VERSION ""

NS_ :

BS_:

BU_: XXX X

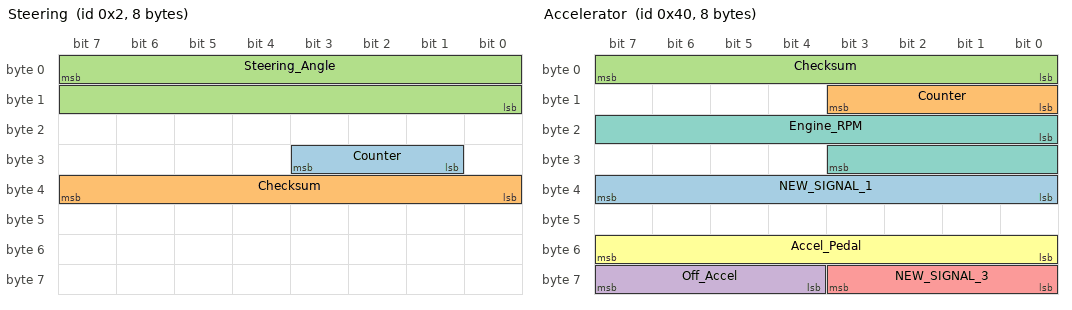
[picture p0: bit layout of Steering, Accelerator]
BO_ 2 Steering: 8 XXX
 SG_ Counter : 25|3@1+ (1,0) [0|7] "" XXX
 SG_ Checksum : 39|8@0+ (1,0) [0|255] "" XXX
 SG_ Steering_Angle : 7|16@0- (0.1,0) [0|65535] "" XXX

BO_ 64 Accelerator: 8 XXX
 SG_ NEW_SIGNAL_1 : 32|8@1+ (1,0) [0|255] "" XXX
 SG_ Counter : 11|4@0+ (1,0) [0|255] "" XXX
 SG_ Checksum : 7|8@0- (1,0) [0|255] "" XXX
 SG_ Off_Accel : 63|4@0+ (1,0) [0|7] "" XXX
 SG_ NEW_SIGNAL_3 : 56|4@1+ (1,0) [0|255] "" XXX
 SG_ Accel_Pedal : 55|8@0+ (1,0) [0|255] "" XXX
 SG_ Engine_RPM : 16|12@1+ (1,0) [0|255] "" XXX

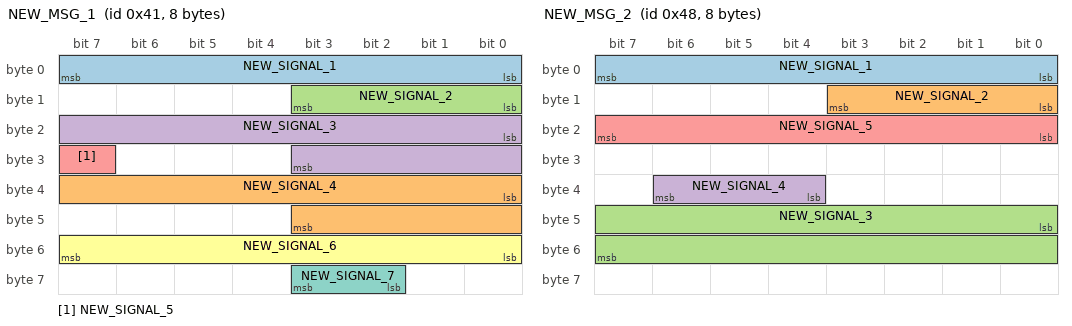
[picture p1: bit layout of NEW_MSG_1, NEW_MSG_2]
BO_ 65 NEW_MSG_1: 8 XXX
 SG_ NEW_SIGNAL_1 : 7|8@0+ (1,0) [0|255] "" XXX
 SG_ NEW_SIGNAL_4 : 32|12@1+ (1,0) [0|255] "" XXX
 SG_ NEW_SIGNAL_2 : 8|4@1+ (1,0) [0|15] "" XXX
 SG_ NEW_SIGNAL_3 : 16|12@1+ (1,0) [0|1] "" XXX
 SG_ NEW_SIGNAL_5 : 31|1@0+ (1,0) [0|15] "" XXX
 SG_ NEW_SIGNAL_6 : 48|8@1+ (1,0) [0|63] "" XXX
 SG_ NEW_SIGNAL_7 : 59|2@0+ (1,0) [0|255] "" XXX

BO_ 72 NEW_MSG_2: 8 XXX
 SG_ NEW_SIGNAL_1 : 7|8@0+ (1,0) [0|255] "" XXX
 SG_ NEW_SIGNAL_2 : 8|4@1+ (1,0) [0|15] "" XXX
 SG_ NEW_SIGNAL_3 : 40|16@1+ (1,0) [0|255] "" XXX
 SG_ NEW_SIGNAL_4 : 38|3@0+ (1,0) [0|255] "" XXX
 SG_ NEW_SIGNAL_5 : 16|8@1+ (1,0) [0|255] "" XXX

BO_ 316 NEW_MSG_3: 8 XXX

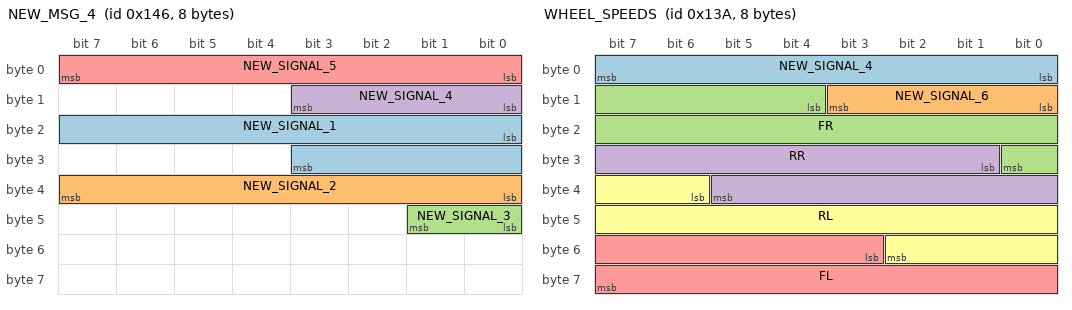
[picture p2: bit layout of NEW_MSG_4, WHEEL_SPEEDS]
BO_ 326 NEW_MSG_4: 8 XXX
 SG_ NEW_SIGNAL_1 : 16|12@1+ (1,0) [0|255] "" XXX
 SG_ NEW_SIGNAL_2 : 32|8@1+ (1,0) [0|255] "" XXX
 SG_ NEW_SIGNAL_3 : 40|2@1+ (1,0) [0|255] "" XXX
 SG_ NEW_SIGNAL_4 : 8|4@1+ (1,0) [0|15] "" XXX
 SG_ NEW_SIGNAL_5 : 7|8@0+ (1,0) [0|255] "" XXX

BO_ 315 G_Sensor: 8 XXX
 SG_ longitudinal : 63|8@0- (1,0) [0|255] "" XXX
 SG_ Latitudinal : 48|8@1- (1,0) [0|255] "" XXX

BO_ 314 WHEEL_SPEEDS: 8 XXX
 SG_ NEW_SIGNAL_4 : 7|8@0+ (1,0) [0|255] "" XXX
 SG_ NEW_SIGNAL_6 : 8|4@1+ (1,0) [0|15] "" XXX
 SG_ FR : 12|13@1+ (0.05747,0) [0|255] "kph" XXX
 SG_ RR : 25|13@1+ (0.05747,0) [0|255] "kph" XXX
 SG_ FL : 51|13@1+ (0.05747,0) [0|255] "kph" XXX
 SG_ RL : 38|13@1+ (0.05747,0) [0|255] "kph" XXX

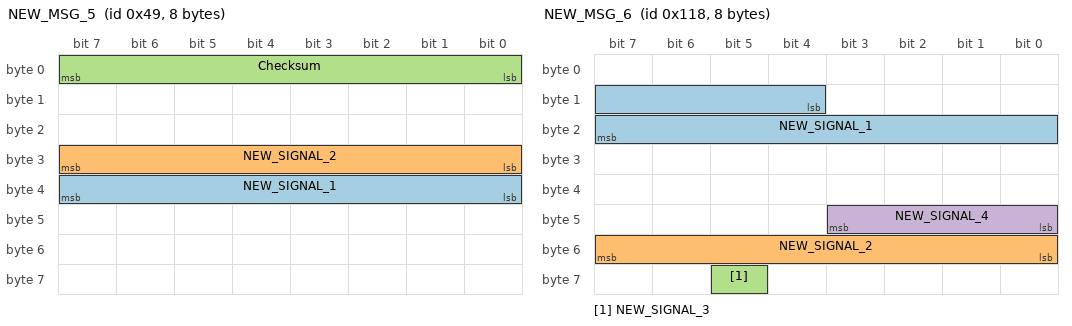
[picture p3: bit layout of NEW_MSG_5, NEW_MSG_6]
BO_ 73 NEW_MSG_5: 8 XXX
 SG_ NEW_SIGNAL_1 : 39|8@0+ (1,0) [0|4095] "" XXX
 SG_ NEW_SIGNAL_2 : 24|8@1+ (1,0) [0|127] "" XXX
 SG_ Checksum : 7|8@0+ (1,0) [0|255] "" XXX

BO_ 280 NEW_MSG_6: 8 XXX
 SG_ NEW_SIGNAL_1 : 12|12@1- (1,0) [0|4095] "" XXX
 SG_ NEW_SIGNAL_2 : 48|8@1- (1,0) [0|255] "" XXX
 SG_ NEW_SIGNAL_3 : 61|1@0+ (1,0) [0|7] "" XXX
 SG_ NEW_SIGNAL_4 : 40|4@1+ (1,0) [0|255] "" XXX

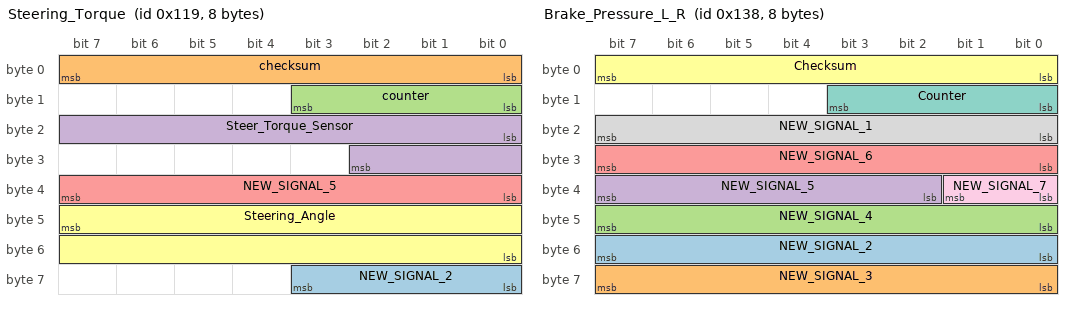
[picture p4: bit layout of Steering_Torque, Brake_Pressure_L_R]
BO_ 281 Steering_Torque: 8 XXX
 SG_ NEW_SIGNAL_2 : 56|4@1+ (1,0) [0|15] "" XXX
 SG_ checksum : 0|8@1+ (1,0) [0|3] "" XXX
 SG_ counter : 8|4@1+ (1,0) [0|15] "" XXX
 SG_ Steer_Torque_Sensor : 16|11@1- (1,0) [0|3] "" XXX
 SG_ NEW_SIGNAL_5 : 39|8@0+ (1,0) [0|127] "" XXX
 SG_ Steering_Angle : 47|16@0- (1,0) [0|255] "" X

BO_ 312 Brake_Pressure_L_R: 8 XXX
 SG_ NEW_SIGNAL_2 : 48|8@1+ (1,0) [0|255] "" XXX
 SG_ NEW_SIGNAL_3 : 56|8@1+ (1,0) [0|255] "" XXX
 SG_ NEW_SIGNAL_4 : 40|8@1+ (1,0) [0|65535] "" XXX
 SG_ NEW_SIGNAL_5 : 39|6@0+ (1,0) [0|255] "" XXX
 SG_ NEW_SIGNAL_6 : 31|8@0+ (1,0) [0|3] "" XXX
 SG_ Checksum : 7|8@0+ (1,0) [0|31] "" XXX
 SG_ Counter : 8|4@1+ (1,0) [0|3] "" XXX
 SG_ NEW_SIGNAL_1 : 23|8@0+ (1,0) [0|255] "" XXX
 SG_ NEW_SIGNAL_7 : 32|2@1+ (1,0) [0|3] "" XXX

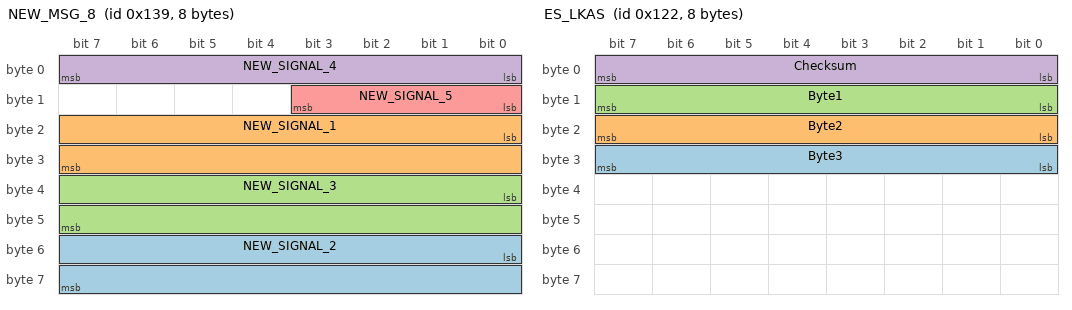
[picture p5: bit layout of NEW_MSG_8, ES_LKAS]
BO_ 313 NEW_MSG_8: 8 XXX
 SG_ NEW_SIGNAL_2 : 48|16@1+ (1,0) [0|255] "" XXX
 SG_ NEW_SIGNAL_1 : 16|16@1+ (1,0) [0|255] "" XXX
 SG_ NEW_SIGNAL_3 : 32|16@1+ (1,0) [0|65535] "" XXX
 SG_ NEW_SIGNAL_4 : 7|8@0+ (1,0) [0|255] "" XXX
 SG_ NEW_SIGNAL_5 : 8|4@1+ (1,0) [0|15] "" XXX

BO_ 290 ES_LKAS: 8 XXX
 SG_ Byte3 : 31|8@0+ (1,0) [0|255] "" XXX
 SG_ Byte2 : 23|8@0+ (1,0) [0|255] "" XXX
 SG_ Byte1 : 15|8@0+ (1,0) [0|255] "" XXX
 SG_ Checksum : 7|8@0+ (1,0) [0|255] "" XXX

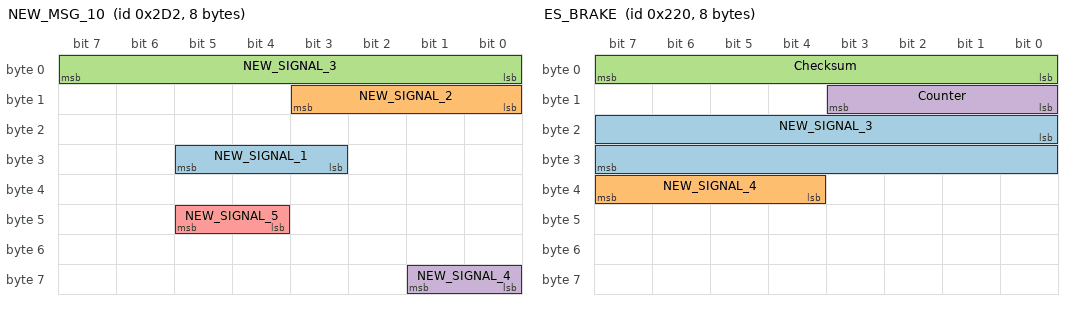
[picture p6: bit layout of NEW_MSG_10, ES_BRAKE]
BO_ 722 NEW_MSG_10: 8 XXX
 SG_ NEW_SIGNAL_1 : 27|3@1+ (1,0) [0|255] "" XXX
 SG_ NEW_SIGNAL_2 : 8|4@1+ (1,0) [0|15] "" XXX
 SG_ NEW_SIGNAL_3 : 0|8@1+ (1,0) [0|255] "" XXX
 SG_ NEW_SIGNAL_4 : 56|2@1+ (1,0) [0|3] "" XXX
 SG_ NEW_SIGNAL_5 : 45|2@0+ (1,0) [0|3] "" XXX

BO_ 544 ES_BRAKE: 8 XXX
 SG_ NEW_SIGNAL_3 : 16|16@1+ (1,0) [0|255] "" XXX
 SG_ NEW_SIGNAL_4 : 36|4@1+ (1,0) [0|63] "" XXX
 SG_ Checksum : 7|8@0+ (1,0) [0|255] "" XXX
 SG_ Counter : 8|4@1+ (1,0) [0|15] "" XXX

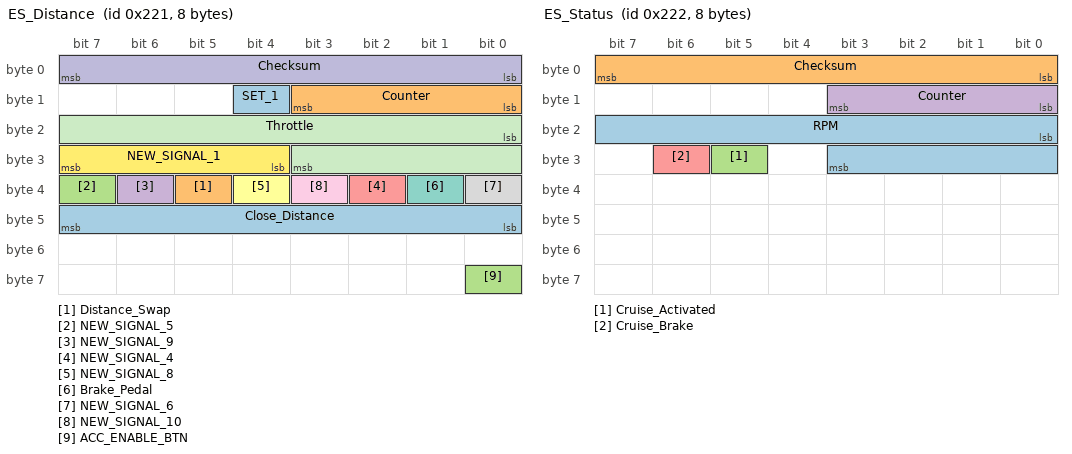
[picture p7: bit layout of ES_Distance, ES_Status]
BO_ 545 ES_Distance: 8 XXX
 SG_ Close_Distance : 47|8@0+ (1,0) [0|255] "" XXX
 SG_ Distance_Swap : 37|1@1+ (1,0) [0|3] "" XXX
 SG_ NEW_SIGNAL_5 : 39|1@0+ (1,0) [0|31] "" XXX
 SG_ NEW_SIGNAL_9 : 38|1@0+ (1,0) [0|3] "" XXX
 SG_ NEW_SIGNAL_4 : 34|1@1+ (1,0) [0|3] "" XXX
 SG_ NEW_SIGNAL_8 : 36|1@0+ (1,0) [0|3] "" XXX
 SG_ Brake_Pedal : 33|1@1+ (1,0) [0|255] "" XXX
 SG_ NEW_SIGNAL_6 : 32|1@1+ (1,0) [0|3] "" XXX
 SG_ NEW_SIGNAL_10 : 35|1@1+ (1,0) [0|3] "" XXX
 SG_ Checksum : 7|8@0+ (1,0) [0|255] "" XXX
 SG_ Throttle : 16|12@1+ (1,0) [0|65535] "" XXX
 SG_ NEW_SIGNAL_1 : 31|4@0+ (1,0) [0|15] "" XXX
 SG_ SET_1 : 12|1@0+ (1,0) [0|3] "" XXX
 SG_ Counter : 8|4@1+ (1,0) [0|15] "" XXX
 SG_ ACC_ENABLE_BTN : 56|1@0+ (1,0) [0|1] "" XXX

BO_ 546 ES_Status: 8 XXX
 SG_ RPM : 16|12@1+ (1,0) [0|255] "" XXX
 SG_ Checksum : 7|8@0+ (1,0) [0|255] "" XXX
 SG_ Cruise_Activated : 29|1@0+ (1,0) [0|3] "" XXX
 SG_ Counter : 8|4@1+ (1,0) [0|15] "" XXX
 SG_ Cruise_Brake : 30|1@0+ (1,0) [0|3] "" XXX

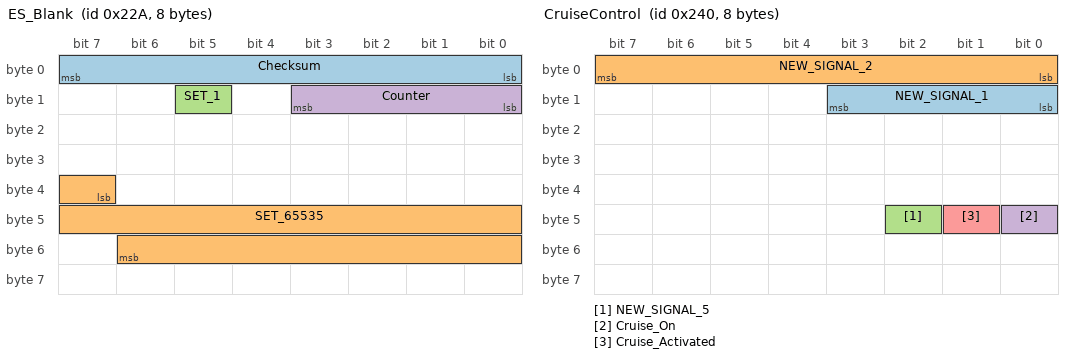
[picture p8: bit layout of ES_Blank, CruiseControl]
BO_ 554 ES_Blank: 8 XXX
 SG_ Checksum : 7|8@0+ (1,0) [0|255] "" XXX
 SG_ SET_65535 : 39|16@1+ (1,0) [0|16777215] "" XXX
 SG_ SET_1 : 13|1@0+ (1,0) [0|7] "" XXX
 SG_ Counter : 8|4@1+ (1,0) [0|15] "" XXX

BO_ 557 NEW_MSG_14: 8 XXX
 SG_ NEW_SIGNAL_1 : 8|4@1+ (1,0) [0|15] "" XXX
 SG_ NEW_SIGNAL_2 : 7|8@0+ (1,0) [0|255] "" XXX

BO_ 576 CruiseControl: 8 XXX
 SG_ NEW_SIGNAL_1 : 8|4@1+ (1,0) [0|15] "" XXX
 SG_ NEW_SIGNAL_2 : 7|8@0+ (1,0) [0|255] "" XXX
 SG_ NEW_SIGNAL_5 : 42|1@1+ (1,0) [0|3] "" XXX
 SG_ Cruise_On : 40|1@1+ (1,0) [0|3] "" XXX
 SG_ Cruise_Activated : 41|1@1+ (1,0) [0|3] "" XXX

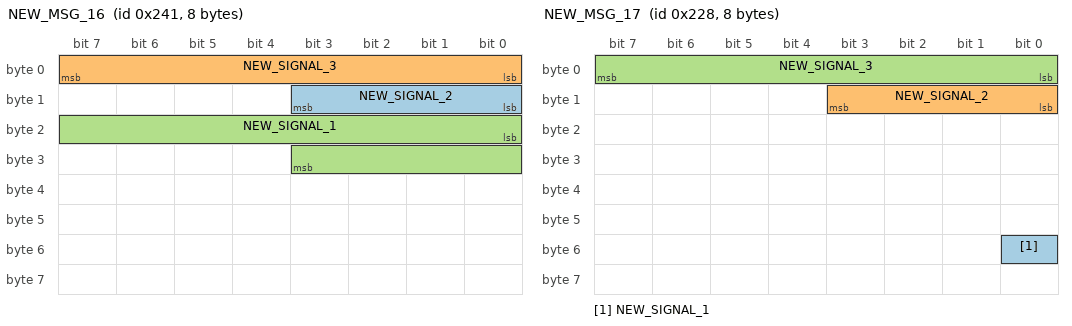
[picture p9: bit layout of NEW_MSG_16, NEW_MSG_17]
BO_ 577 NEW_MSG_16: 8 XXX
 SG_ NEW_SIGNAL_2 : 8|4@1+ (1,0) [0|15] "" XXX
 SG_ NEW_SIGNAL_3 : 7|8@0+ (1,0) [0|255] "" XXX
 SG_ NEW_SIGNAL_1 : 16|12@1+ (1,0) [0|255] "" XXX

BO_ 552 NEW_MSG_17: 8 XXX
 SG_ NEW_SIGNAL_1 : 48|1@1+ (1,0) [0|3] "" XXX
 SG_ NEW_SIGNAL_2 : 8|4@1+ (1,0) [0|15] "" XXX
 SG_ NEW_SIGNAL_3 : 7|8@0+ (1,0) [0|255] "" XXX

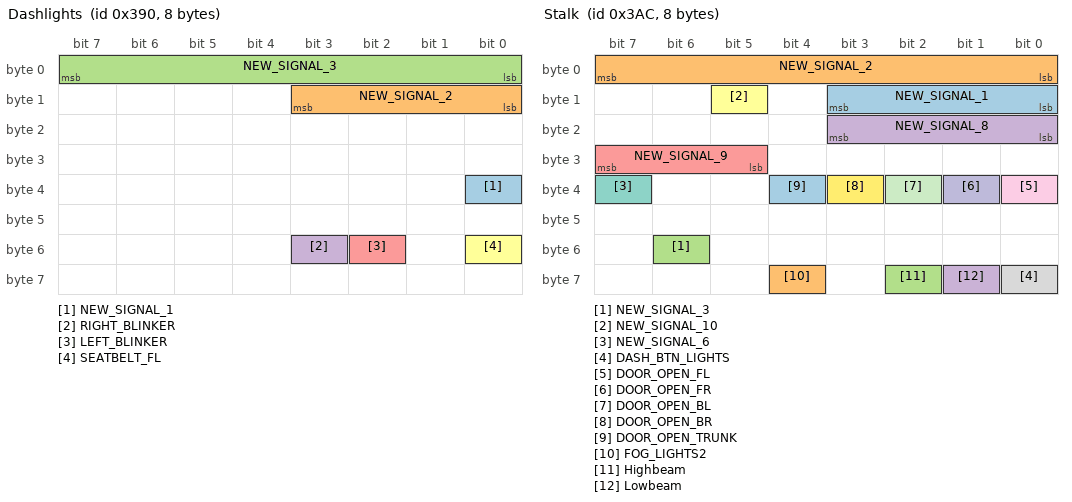
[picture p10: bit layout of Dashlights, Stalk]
BO_ 912 Dashlights: 8 XXX
 SG_ NEW_SIGNAL_1 : 32|1@1+ (1,0) [0|3] "" XXX
 SG_ NEW_SIGNAL_2 : 8|4@1+ (1,0) [0|15] "" XXX
 SG_ NEW_SIGNAL_3 : 7|8@0+ (1,0) [0|255] "" XXX
 SG_ RIGHT_BLINKER : 51|1@0+ (1,0) [0|1] "" XXX
 SG_ LEFT_BLINKER : 50|1@0+ (1,0) [0|3] "" XXX
 SG_ SEATBELT_FL : 48|1@0+ (1,0) [0|1] "" XXX

BO_ 940 Stalk: 8 XXX
 SG_ NEW_SIGNAL_1 : 8|4@1+ (1,0) [0|15] "" XXX
 SG_ NEW_SIGNAL_2 : 7|8@0+ (1,0) [0|255] "" XXX
 SG_ NEW_SIGNAL_3 : 54|1@0+ (1,0) [0|7] "" XXX
 SG_ NEW_SIGNAL_8 : 16|4@1+ (1,0) [0|15] "" XXX
 SG_ NEW_SIGNAL_9 : 31|3@0+ (1,0) [0|7] "" XXX
 SG_ NEW_SIGNAL_10 : 13|1@0+ (1,0) [0|3] "" XXX
 SG_ NEW_SIGNAL_6 : 39|1@0+ (1,0) [0|7] "" XXX
 SG_ DASH_BTN_LIGHTS : 56|1@0+ (1,0) [0|1] "" XXX
 SG_ DOOR_OPEN_FL : 32|1@1+ (1,0) [0|255] "" XXX
 SG_ DOOR_OPEN_FR : 33|1@1+ (1,0) [0|3] "" XXX
 SG_ DOOR_OPEN_BL : 34|1@0+ (1,0) [0|1] "" XXX
 SG_ DOOR_OPEN_BR : 35|1@0+ (1,0) [0|1] "" XXX
 SG_ DOOR_OPEN_TRUNK : 36|1@0+ (1,0) [0|1] "" XXX
 SG_ FOG_LIGHTS2 : 60|1@0+ (1,0) [0|1] "" XXX
 SG_ Highbeam : 58|1@0+ (1,0) [0|1] "" XXX
 SG_ Lowbeam : 57|1@1+ (1,0) [0|3] "" XXX

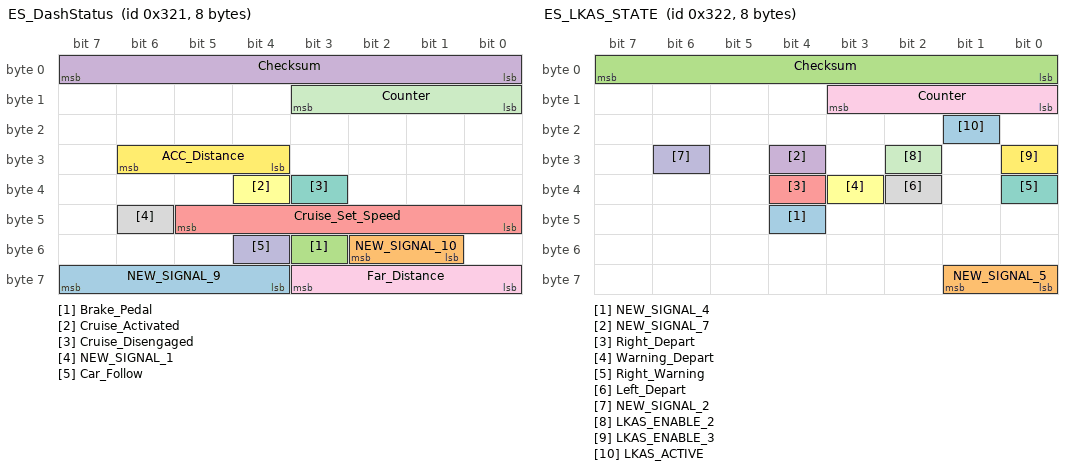
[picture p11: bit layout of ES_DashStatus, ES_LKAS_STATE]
BO_ 801 ES_DashStatus: 8 XXX
 SG_ NEW_SIGNAL_9 : 63|4@0+ (1,0) [0|15] "" XXX
 SG_ NEW_SIGNAL_10 : 49|2@1+ (1,0) [0|3] "" XXX
 SG_ Brake_Pedal : 51|1@0+ (1,0) [0|3] "" XXX
 SG_ Checksum : 7|8@0+ (1,0) [0|255] "" XXX
 SG_ Cruise_Set_Speed : 45|6@0+ (1,0) [0|3] "" XXX
 SG_ Cruise_Activated : 36|1@0+ (1,0) [0|3] "" XXX
 SG_ Cruise_Disengaged : 35|1@1+ (1,0) [0|3] "" XXX
 SG_ NEW_SIGNAL_1 : 46|1@0+ (1,0) [0|3] "" XXX
 SG_ Far_Distance : 56|4@1+ (1,0) [0|15] "" XXX
 SG_ Car_Follow : 52|1@0+ (1,0) [0|3] "" XXX
 SG_ Counter : 8|4@1+ (1,0) [0|7] "" XXX
 SG_ ACC_Distance : 30|3@0+ (1,0) [0|3] "" XXX

BO_ 802 ES_LKAS_STATE: 8 XXX
 SG_ NEW_SIGNAL_4 : 44|1@0+ (1,0) [0|3] "" XXX
 SG_ NEW_SIGNAL_5 : 56|2@1+ (1,0) [0|3] "" XXX
 SG_ Checksum : 7|8@0+ (1,0) [0|255] "" XXX
 SG_ NEW_SIGNAL_7 : 28|1@0+ (1,0) [0|3] "" XXX
 SG_ Right_Depart : 36|1@0+ (1,0) [0|3] "" XXX
 SG_ Warning_Depart : 35|1@1+ (1,0) [0|3] "" XXX
 SG_ Right_Warning : 32|1@1+ (1,0) [0|15] "" XXX
 SG_ Left_Depart : 34|1@1+ (1,0) [0|3] "" XXX
 SG_ Counter : 8|4@1+ (1,0) [0|15] "" XXX
 SG_ NEW_SIGNAL_2 : 30|1@0+ (1,0) [0|3] "" XXX
 SG_ LKAS_ENABLE_2 : 26|1@0+ (1,0) [0|1] "" XXX
 SG_ LKAS_ENABLE_3 : 24|1@0+ (1,0) [0|1] "" XXX
 SG_ LKAS_ACTIVE : 17|1@1+ (1,0) [0|3] "" XXX

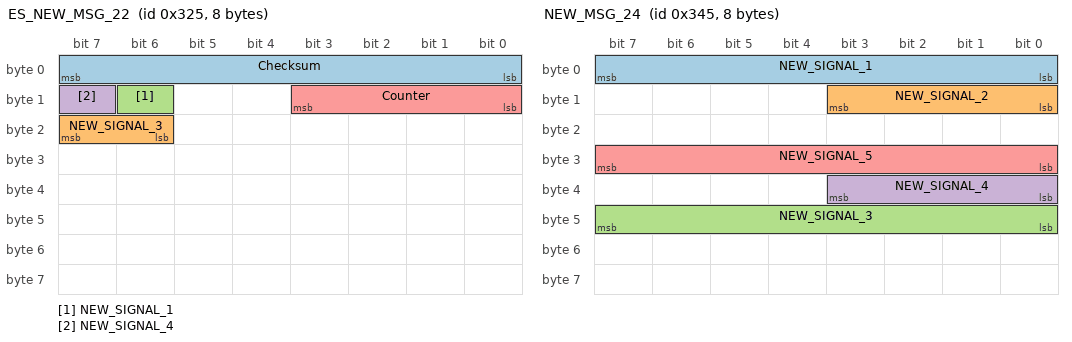
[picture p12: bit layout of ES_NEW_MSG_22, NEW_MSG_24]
BO_ 805 ES_NEW_MSG_22: 8 XXX
 SG_ Checksum : 7|8@0+ (1,0) [0|255] "" XXX
 SG_ NEW_SIGNAL_3 : 23|2@0+ (1,0) [0|3] "" XXX
 SG_ NEW_SIGNAL_1 : 14|1@0+ (1,0) [0|3] "" XXX
 SG_ NEW_SIGNAL_4 : 15|1@0+ (1,0) [0|3] "" XXX
 SG_ Counter : 8|4@1+ (1,0) [0|15] "" XXX

BO_ 808 NEW_MSG_23: 8 XXX
 SG_ NEW_SIGNAL_1 : 7|8@0+ (1,0) [0|255] "" XXX
 SG_ NEW_SIGNAL_2 : 8|4@1+ (1,0) [0|15] "" XXX

BO_ 837 NEW_MSG_24: 8 XXX
 SG_ NEW_SIGNAL_1 : 7|8@0+ (1,0) [0|255] "" XXX
 SG_ NEW_SIGNAL_2 : 8|4@1+ (1,0) [0|15] "" XXX
 SG_ NEW_SIGNAL_3 : 40|8@1+ (1,0) [0|255] "" XXX
 SG_ NEW_SIGNAL_4 : 32|4@1+ (1,0) [0|15] "" XXX
 SG_ NEW_SIGNAL_5 : 24|8@1+ (1,0) [0|255] "" XXX

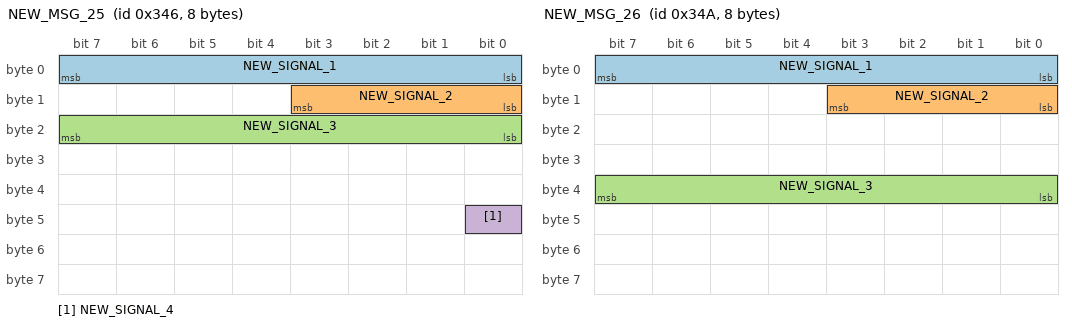
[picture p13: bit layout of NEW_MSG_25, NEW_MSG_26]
BO_ 838 NEW_MSG_25: 8 XXX
 SG_ NEW_SIGNAL_1 : 7|8@0+ (1,0) [0|255] "" XXX
 SG_ NEW_SIGNAL_2 : 8|4@1+ (1,0) [0|15] "" XXX
 SG_ NEW_SIGNAL_3 : 16|8@1+ (1,0) [0|255] "" XXX
 SG_ NEW_SIGNAL_4 : 40|1@1+ (1,0) [0|3] "" XXX

BO_ 842 NEW_MSG_26: 8 XXX
 SG_ NEW_SIGNAL_1 : 7|8@0+ (1,0) [0|255] "" XXX
 SG_ NEW_SIGNAL_2 : 8|4@1+ (1,0) [0|15] "" XXX
 SG_ NEW_SIGNAL_3 : 32|8@1+ (1,0) [0|255] "" XXX

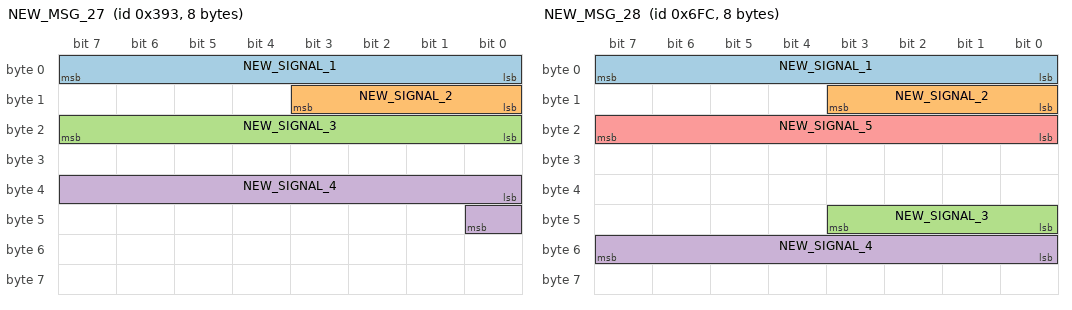
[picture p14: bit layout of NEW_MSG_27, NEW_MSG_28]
BO_ 915 NEW_MSG_27: 8 XXX
 SG_ NEW_SIGNAL_1 : 0|8@1+ (1,0) [0|255] "" XXX
 SG_ NEW_SIGNAL_2 : 8|4@1+ (1,0) [0|15] "" XXX
 SG_ NEW_SIGNAL_3 : 16|8@1+ (1,0) [0|255] "" XXX
 SG_ NEW_SIGNAL_4 : 32|9@1+ (1,0) [0|255] "" XXX

BO_ 1788 NEW_MSG_28: 8 XXX
 SG_ NEW_SIGNAL_1 : 7|8@0+ (1,0) [0|255] "" XXX
 SG_ NEW_SIGNAL_2 : 8|4@1+ (1,0) [0|15] "" XXX
 SG_ NEW_SIGNAL_3 : 40|4@1+ (1,0) [0|15] "" XXX
 SG_ NEW_SIGNAL_4 : 48|8@1+ (1,0) [0|255] "" XXX
 SG_ NEW_SIGNAL_5 : 16|8@1+ (1,0) [0|255] "" XXX

BO_ 816 NEW_MSG_29: 8 XXX
 SG_ NEW_SIGNAL_1 : 7|8@0+ (1,0) [0|255] "" XXX
 SG_ NEW_SIGNAL_2 : 8|4@1+ (1,0) [0|15] "" XXX

BO_ 826 NEW_MSG_30: 8 XXX
 SG_ NEW_SIGNAL_1 : 8|4@1+ (1,0) [0|15] "" XXX
 SG_ NEW_SIGNAL_2 : 0|8@1+ (1,0) [0|255] "" XXX

BO_ 839 NEW_MSG_31: 8 XXX
 SG_ NEW_SIGNAL_1 : 0|8@1+ (1,0) [0|255] "" XXX
 SG_ NEW_SIGNAL_2 : 8|4@1+ (1,0) [0|15] "" XXX

BO_ 2015 NEW_MSG_32: 8 XXX
 SG_ NEW_SIGNAL_2 : 16|8@1+ (1,0) [0|255] "" XXX

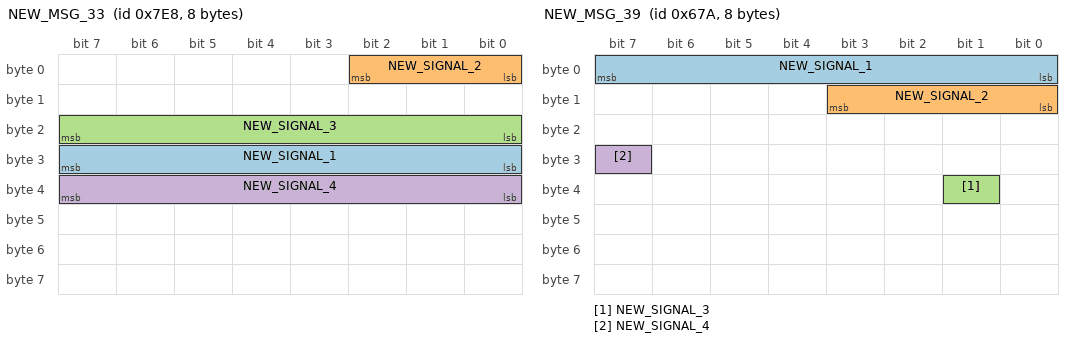
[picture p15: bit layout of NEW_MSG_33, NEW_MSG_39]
BO_ 2024 NEW_MSG_33: 8 XXX
 SG_ NEW_SIGNAL_1 : 31|8@0+ (1,0) [0|255] "" XXX
 SG_ NEW_SIGNAL_2 : 0|3@1+ (1,0) [0|15] "" XXX
 SG_ NEW_SIGNAL_3 : 16|8@1+ (1,0) [0|255] "" XXX
 SG_ NEW_SIGNAL_4 : 32|8@1+ (1,0) [0|255] "" XXX

BO_ 1614 NEW_MSG_34: 8 XXX
 SG_ NEW_SIGNAL_1 : 0|8@1+ (1,0) [0|255] "" XXX
 SG_ NEW_SIGNAL_2 : 8|4@1+ (1,0) [0|15] "" XXX

BO_ 1617 NEW_MSG_35: 8 XXX
 SG_ NEW_SIGNAL_1 : 0|8@1+ (1,0) [0|255] "" XXX
 SG_ NEW_SIGNAL_2 : 8|4@1+ (1,0) [0|15] "" XXX

BO_ 1632 NEW_MSG_36: 8 XXX
 SG_ NEW_SIGNAL_1 : 55|16@0+ (1,0) [0|255] "" XXX

BO_ 1650 NEW_MSG_37: 8 XXX
 SG_ NEW_SIGNAL_1 : 0|8@1+ (1,0) [0|255] "" XXX
 SG_ NEW_SIGNAL_2 : 8|4@1+ (1,0) [0|15] "" XXX

BO_ 1657 NEW_MSG_38: 8 XXX
 SG_ NEW_SIGNAL_1 : 0|8@1+ (1,0) [0|255] "" XXX
 SG_ NEW_SIGNAL_2 : 8|4@1+ (1,0) [0|15] "" XXX

BO_ 1658 NEW_MSG_39: 8 XXX
 SG_ NEW_SIGNAL_1 : 0|8@1+ (1,0) [0|255] "" XXX
 SG_ NEW_SIGNAL_2 : 8|4@1+ (1,0) [0|15] "" XXX
 SG_ NEW_SIGNAL_3 : 33|1@1+ (1,0) [0|3] "" XXX
 SG_ NEW_SIGNAL_4 : 31|1@0+ (1,0) [0|3] "" XXX

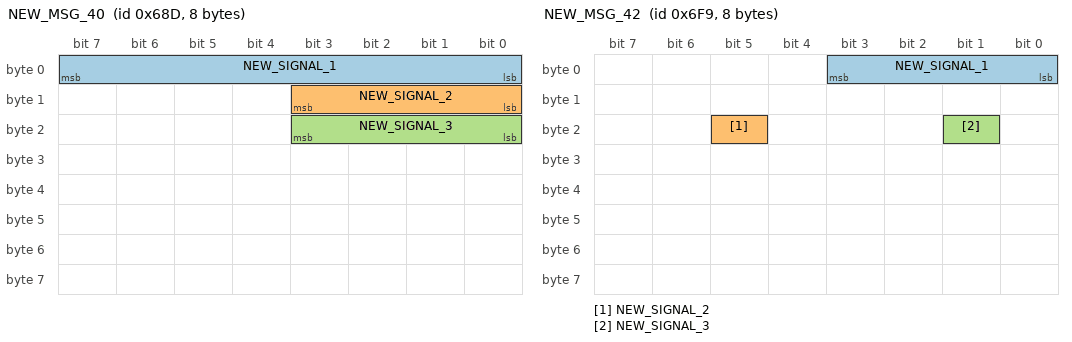
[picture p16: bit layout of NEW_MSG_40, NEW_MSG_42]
BO_ 1677 NEW_MSG_40: 8 XXX
 SG_ NEW_SIGNAL_1 : 0|8@1+ (1,0) [0|255] "" XXX
 SG_ NEW_SIGNAL_2 : 8|4@1+ (1,0) [0|15] "" XXX
 SG_ NEW_SIGNAL_3 : 16|4@1+ (1,0) [0|15] "" XXX

BO_ 1743 NEW_MSG_41: 8 XXX
 SG_ NEW_SIGNAL_1 : 0|8@1+ (1,0) [0|127] "" XXX
 SG_ NEW_SIGNAL_2 : 8|4@1+ (1,0) [0|15] "" XXX

BO_ 1785 NEW_MSG_42: 8 XXX
 SG_ NEW_SIGNAL_1 : 0|4@1+ (1,0) [0|255] "" XXX
 SG_ NEW_SIGNAL_2 : 21|1@1+ (1,0) [0|31] "" XXX
 SG_ NEW_SIGNAL_3 : 17|1@1+ (1,0) [0|7] "" XXX

BO_ 1759 NEW_MSG_43: 8 XXX
 SG_ NEW_SIGNAL_1 : 17|1@1+ (1,0) [0|3] "" XXX

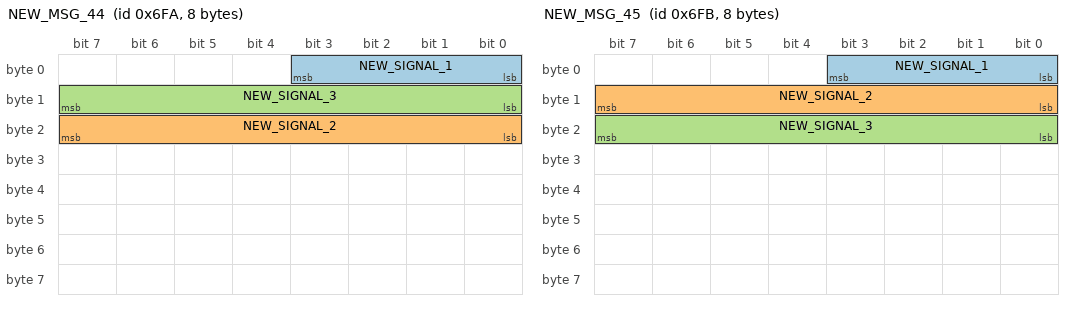
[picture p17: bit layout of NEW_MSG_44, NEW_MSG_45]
BO_ 1786 NEW_MSG_44: 8 XXX
 SG_ NEW_SIGNAL_1 : 0|4@1+ (1,0) [0|15] "" XXX
 SG_ NEW_SIGNAL_2 : 16|8@1+ (1,0) [0|255] "" XXX
 SG_ NEW_SIGNAL_3 : 8|8@1+ (1,0) [0|15] "" XXX

BO_ 1787 NEW_MSG_45: 8 XXX
 SG_ NEW_SIGNAL_1 : 0|4@1+ (1,0) [0|15] "" XXX
 SG_ NEW_SIGNAL_2 : 8|8@1+ (1,0) [0|255] "" XXX
 SG_ NEW_SIGNAL_3 : 16|8@1+ (1,0) [0|255] "" XXX

CM_ SG_ 544 Counter "20hz";
CM_ SG_ 545 Counter "20hz";
CM_ SG_ 546 Counter "20hz";
CM_ SG_ 554 Counter "20hz";
CM_ SG_ 940 FOG_LIGHTS2 "yellow fog light in the dash";
CM_ SG_ 940 Highbeam "01 = low beam, 11 = high beam";
CM_ SG_ 801 Counter "10hz";
CM_ SG_ 802 Counter "10hz";
CM_ SG_ 805 NEW_SIGNAL_3 "always 3";
CM_ SG_ 805 NEW_SIGNAL_4 "always 1";
CM_ SG_ 805 Counter "10hz";
